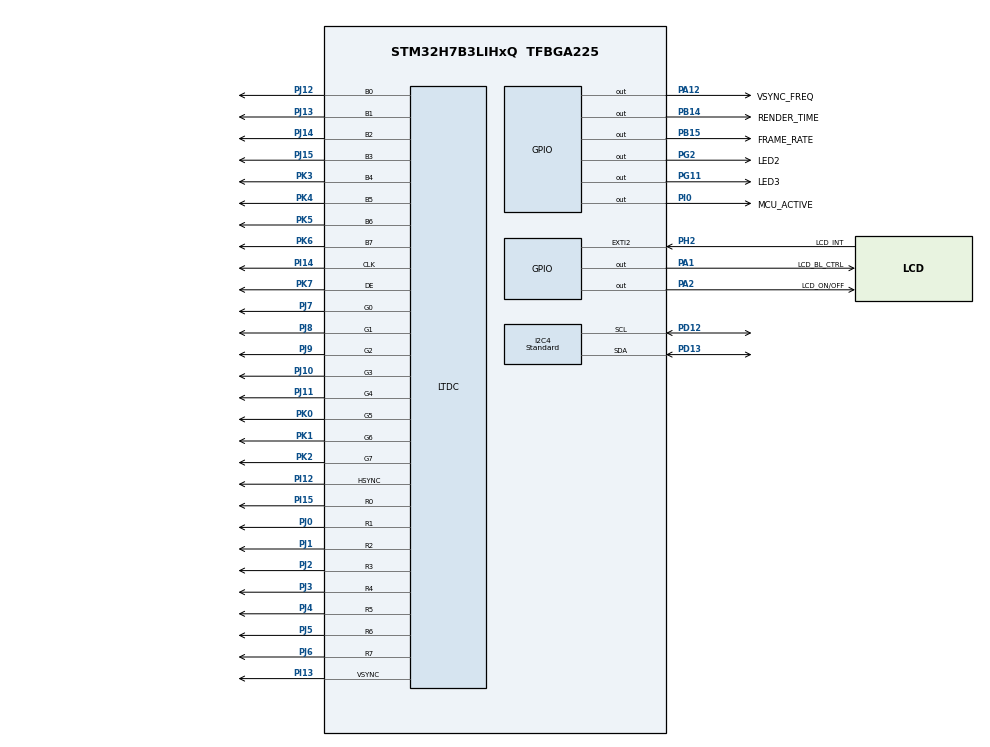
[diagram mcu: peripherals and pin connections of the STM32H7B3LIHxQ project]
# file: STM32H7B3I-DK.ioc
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CORTEX_M7.AccessPermission-Cortex_Memory_Protection_Unit_Region1_Settings=MPU_REGION_FULL_ACCESS
CORTEX_M7.AccessPermission-Cortex_Memory_Protection_Unit_Region2_Settings=MPU_REGION_FULL_ACCESS
CORTEX_M7.AccessPermission-Cortex_Memory_Protection_Unit_Region3_Settings=MPU_REGION_FULL_ACCESS
CORTEX_M7.BaseAddress-Cortex_Memory_Protection_Unit_Region0_Settings=0x90000000
CORTEX_M7.BaseAddress-Cortex_Memory_Protection_Unit_Region1_Settings=0x90000000
CORTEX_M7.BaseAddress-Cortex_Memory_Protection_Unit_Region2_Settings=0x24000000
CORTEX_M7.BaseAddress-Cortex_Memory_Protection_Unit_Region3_Settings=0x24000000
CORTEX_M7.CPU_DCache=Enabled
CORTEX_M7.CPU_ICache=Enabled
CORTEX_M7.DisableExec-Cortex_Memory_Protection_Unit_Region0_Settings=MPU_INSTRUCTION_ACCESS_DISABLE
CORTEX_M7.DisableExec-Cortex_Memory_Protection_Unit_Region1_Settings=MPU_INSTRUCTION_ACCESS_DISABLE
CORTEX_M7.DisableExec-Cortex_Memory_Protection_Unit_Region2_Settings=MPU_INSTRUCTION_ACCESS_DISABLE
CORTEX_M7.DisableExec-Cortex_Memory_Protection_Unit_Region3_Settings=MPU_INSTRUCTION_ACCESS_DISABLE
CORTEX_M7.Enable-Cortex_Memory_Protection_Unit_Region0_Settings=MPU_REGION_ENABLE
CORTEX_M7.Enable-Cortex_Memory_Protection_Unit_Region1_Settings=MPU_REGION_ENABLE
CORTEX_M7.Enable-Cortex_Memory_Protection_Unit_Region2_Settings=MPU_REGION_ENABLE
CORTEX_M7.Enable-Cortex_Memory_Protection_Unit_Region3_Settings=MPU_REGION_ENABLE
CORTEX_M7.IsBufferable-Cortex_Memory_Protection_Unit_Region3_Settings=MPU_ACCESS_BUFFERABLE
CORTEX_M7.IsCacheable-Cortex_Memory_Protection_Unit_Region1_Settings=MPU_ACCESS_CACHEABLE
CORTEX_M7.IsCacheable-Cortex_Memory_Protection_Unit_Region2_Settings=MPU_ACCESS_CACHEABLE
CORTEX_M7.IsCacheable-Cortex_Memory_Protection_Unit_Region3_Settings=MPU_ACCESS_CACHEABLE
CORTEX_M7.MPU_Control=MPU_PRIVILEGED_DEFAULT
CORTEX_M7.Size-Cortex_Memory_Protection_Unit_Region0_Settings=MPU_REGION_SIZE_256MB
CORTEX_M7.Size-Cortex_Memory_Protection_Unit_Region1_Settings=MPU_REGION_SIZE_64MB
CORTEX_M7.Size-Cortex_Memory_Protection_Unit_Region2_Settings=MPU_REGION_SIZE_1MB
CORTEX_M7.Size-Cortex_Memory_Protection_Unit_Region3_Settings=MPU_REGION_SIZE_256KB
DMA2D.ColorMode=DMA2D_OUTPUT_RGB565
FREERTOS.Tasks01=GUI_Task,24,4096,TouchGFX_Task,As weak,NULL,Dynamic,NULL,NULL
FREERTOS.configTOTAL_HEAP_SIZE=32768
I2C4.Analog_Filter=I2C_ANALOGFILTER_DISABLE
I2C4.I2C_Fall_Time=0
I2C4.I2C_Rise_Time=0
I2C4.I2C_Speed_Mode=I2C_Standard
I2C4.Speed=100
I2C4.Timing=0x30808BD0
LTDC.ActiveH=272
LTDC.ActiveW=480
LTDC.Alpha_L0=255
LTDC.BlendingFactor1_L0=LTDC_BLENDING_FACTOR1_CA
LTDC.BlendingFactor2_L0=LTDC_BLENDING_FACTOR2_CA
LTDC.Blue_L0=255
LTDC.HBP=2
LTDC.HFP=32
LTDC.HSync=41
LTDC.ImageHeight_L0=272
LTDC.ImageWidth_L0=480
LTDC.Layers=0
LTDC.PixelFormat_L0=LTDC_PIXEL_FORMAT_RGB888
LTDC.VSync=10
LTDC.WindowX1_L0=480
LTDC.WindowY1_L0=272
Mcu.Family=STM32H7
Mcu.Name=STM32H7B3LIHxQ
Mcu.Package=TFBGA225
NVIC.DMA2D_IRQn=true\:5\:0\:true\:false\:true\:true\:true\:true
NVIC.EXTI2_IRQn=true\:5\:0\:false\:false\:true\:true\:true\:true
NVIC.LTDC_IRQn=true\:5\:0\:false\:false\:true\:true\:true\:true
NVIC.OCTOSPI1_IRQn=true\:5\:0\:false\:false\:true\:true\:true\:true
NVIC.PriorityGroup=NVIC_PRIORITYGROUP_4
NVIC.TIM6_DAC_IRQn=true\:0\:0\:false\:false\:true\:false\:false\:true
NVIC.TimeBase=TIM6_DAC_IRQn
NVIC.TimeBaseIP=TIM6
OCTOSPI1.ChipSelectBoundary=0
OCTOSPI1.ChipSelectHighTime=2
OCTOSPI1.ClockPrescaler=3
OCTOSPI1.DeviceSize=26
OCTOSPI1.Refresh=0
PA1.GPIO_Label=LCD_BL_CTRL
PA1.GPIO_ModeDefaultOutputPP=GPIO_MODE_OUTPUT_PP
PA1.GPIO_PuPd=GPIO_NOPULL
PA1.GPIO_Speed=GPIO_SPEED_FREQ_LOW
PA1.PinState=GPIO_PIN_RESET
PA1.Signal=GPIO_Output
PA12.GPIO_Label=VSYNC_FREQ
PA12.Signal=GPIO_Output
PA2.GPIO_Label=LCD_ON/OFF
PA2.GPIO_ModeDefaultOutputPP=GPIO_MODE_OUTPUT_PP
PA2.GPIO_PuPd=GPIO_PULLUP
PA2.GPIO_Speed=GPIO_SPEED_FREQ_LOW
PA2.PinState=GPIO_PIN_RESET
PA2.Signal=GPIO_Output
PB14.GPIO_Label=RENDER_TIME
PB14.Signal=GPIO_Output
PB15.GPIO_Label=FRAME_RATE
PB15.Signal=GPIO_Output
PD12.GPIO_Speed=GPIO_SPEED_FREQ_HIGH
PD12.Mode=I2C
PD12.Signal=I2C4_SCL
PD13.GPIO_Speed=GPIO_SPEED_FREQ_HIGH
PD13.Mode=I2C
PD13.Signal=I2C4_SDA
PG11.GPIO_Label=LED3
PG11.Signal=GPIO_Output
PG2.GPIO_Label=LED2
PG2.Signal=GPIO_Output
PH0-OSC_IN.Mode=HSE-External-Oscillator
PH0-OSC_IN.Signal=RCC_OSC_IN
PH1-OSC_OUT.Mode=HSE-External-Oscillator
PH1-OSC_OUT.Signal=RCC_OSC_OUT
PH2.GPIO_Label=LCD_INT
PH2.GPIO_PuPd=GPIO_PULLUP
PH2.Signal=GPXTI2
PI0.GPIO_Label=MCU_ACTIVE
PI0.Signal=GPIO_Output
PI12.Mode=RGB888
PI12.Signal=LTDC_HSYNC
PI13.Mode=RGB888
PI13.Signal=LTDC_VSYNC
PI14.Mode=RGB888
PI14.Signal=LTDC_CLK
PI15.Mode=RGB888
PI15.Signal=LTDC_R0
PJ0.Mode=RGB888
PJ0.Signal=LTDC_R1
PJ1.Mode=RGB888
PJ1.Signal=LTDC_R2
PJ10.Mode=RGB888
PJ10.Signal=LTDC_G3
PJ11.Mode=RGB888
PJ11.Signal=LTDC_G4
PJ12.Mode=RGB888
PJ12.Signal=LTDC_B0
PJ13.Mode=RGB888
PJ13.Signal=LTDC_B1
PJ14.Mode=RGB888
PJ14.Signal=LTDC_B2
PJ15.Mode=RGB888
PJ15.Signal=LTDC_B3
PJ2.Mode=RGB888
PJ2.Signal=LTDC_R3
PJ3.Mode=RGB888
PJ3.Signal=LTDC_R4
PJ4.Mode=RGB888
PJ4.Signal=LTDC_R5
PJ5.Mode=RGB888
PJ5.Signal=LTDC_R6
PJ6.Mode=RGB888
PJ6.Signal=LTDC_R7
PJ7.Mode=RGB888
PJ7.Signal=LTDC_G0
PJ8.Mode=RGB888
PJ8.Signal=LTDC_G1
PJ9.Mode=RGB888
PJ9.Signal=LTDC_G2
PK0.Mode=RGB888
PK0.Signal=LTDC_G5
PK1.Mode=RGB888
PK1.Signal=LTDC_G6
PK2.Mode=RGB888
PK2.Signal=LTDC_G7
PK3.Mode=RGB888
PK3.Signal=LTDC_B4
PK4.Mode=RGB888
PK4.Signal=LTDC_B5
PK5.Mode=RGB888
PK5.Signal=LTDC_B6
PK6.Mode=RGB888
PK6.Signal=LTDC_B7
PK7.GPIO_PuPd=GPIO_NOPULL
PK7.Mode=RGB888
PK7.Signal=LTDC_DE
ProjectManager.HeapSize=0x1000
ProjectManager.StackSize=0x1000
ProjectManager.TargetToolchain=STM32CubeIDE
RCC.ADCFreq_Value=133000000
RCC.APB1Freq_Value=140000000
RCC.APB2Freq_Value=140000000
RCC.APB3Freq_Value=140000000
RCC.APB4Freq_Value=140000000
RCC.CKPERSourceSelection=RCC_CLKPSOURCE_HSE
RCC.CortexFreq_Value=280000000
RCC.DIVM1=12
RCC.DIVM2=24
RCC.DIVM3=24
RCC.DIVN1=280
RCC.DIVN2=266
RCC.DIVN3=201
RCC.DIVR3=21
RCC.HCLKFreq_Value=140000000
RCC.HPRE=RCC_HCLK_DIV2
RCC.HSIDiv=RCC_PLLSAIDIVR_2
RCC.PLL2FRACN=0
RCC.PLL3FRACN=5462
RCC.PLLFRACN=0
RCC.PLLSourceVirtual=RCC_PLLSOURCE_HSE
RCC.PWR_Regulator_Voltage_Scale=PWR_REGULATOR_VOLTAGE_SCALE0
RCC.QSPICLockSelection=RCC_OSPICLKSOURCE_PLL2
RCC.SYSCLKFreq_VALUE=280000000
RCC.SYSCLKSource=RCC_SYSCLKSOURCE_PLLCLK
RCC.SupplySource=PWR_DIRECT_SMPS_SUPPLY
RCC.USBFreq_Value=280000000
STMicroelectronics.X-CUBE-TOUCHGFX.4.15.0.ApplicationCcGraphicsJjApplication=TouchGFXOoGenerator
STMicroelectronics.X-CUBE-TOUCHGFX.4.15.0.tgfx_address1=0x24040000
STMicroelectronics.X-CUBE-TOUCHGFX.4.15.0.tgfx_address2=0x2409FA00
STMicroelectronics.X-CUBE-TOUCHGFX.4.15.0.tgfx_buffering_strategy=Double
STMicroelectronics.X-CUBE-TOUCHGFX.4.15.0.tgfx_display_interface=disp_ltdc
STMicroelectronics.X-CUBE-TOUCHGFX.4.15.0.tgfx_hardware_accelerator=dma_2d
STMicroelectronics.X-CUBE-TOUCHGFX.4.15.0.tgfx_location=Allocate
STMicroelectronics.X-CUBE-TOUCHGFX.4.15.0.tgfx_pixel_format=RGB888\:24
STMicroelectronics.X-CUBE-TOUCHGFX.4.15.0.tgfx_vsync=vsync_ltdc
VP_CRC_VS_CRC.Mode=CRC_Activate
VP_DMA2D_VS_DMA2D.Mode=DMA2D_Activate
VP_FREERTOS_VS_CMSIS_V2.Mode=CMSIS_V2
VP_OCTOSPI1_VS_octo.Mode=octo_mode
VP_STMicroelectronics.X-CUBE-TOUCHGFX_VS_GraphicsJjApplication_4.15.0.Mode=GraphicsJjApplication
VP_SYS_VS_tim6.Mode=TIM6
board=custom

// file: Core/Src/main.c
/* USER CODE BEGIN Header */
/**
  ******************************************************************************
  * @file           : main.c
  * @brief          : Main program body
  ******************************************************************************
  * @attention
  *
  * <h2><center>&copy; Copyright (c) 2019 STMicroelectronics.
  * All rights reserved.</center></h2>
  *
  * This software component is licensed by ST under Ultimate Liberty license
  * SLA0044, the "License"; You may not use this file except in compliance with
  * the License. You may obtain a copy of the License at:
  *                             www.st.com/SLA0044
  *
  ******************************************************************************
  */
/* USER CODE END Header */
#include "main.h"
#include "cmsis_os.h"
#include "app_touchgfx.h"

/* USER CODE BEGIN Includes */
#include "stm32h7b3i_discovery_ospi.h"
/* USER CODE END Includes */

CRC_HandleTypeDef hcrc;

DMA2D_HandleTypeDef hdma2d;

I2C_HandleTypeDef hi2c4;

LTDC_HandleTypeDef hltdc;

OSPI_HandleTypeDef hospi1;

/* Definitions for GUI_Task */
osThreadId_t GUI_TaskHandle;
const osThreadAttr_t GUI_Task_attributes = {
  .name = "GUI_Task",
  .priority = (osPriority_t) osPriorityNormal,
  .stack_size = 4096 * 4
};

void SystemClock_Config(void);
static void MPU_Config(void);
static void MX_CRC_Init(void);
static void MX_GPIO_Init(void);
static void MX_DMA2D_Init(void);
static void MX_LTDC_Init(void);
static void MX_I2C4_Init(void);
static void MX_OCTOSPI1_Init(void);
void TouchGFX_Task(void *argument);

int main(void)
{

  /* MPU Configuration--------------------------------------------------------*/
  MPU_Config();

  /* Enable I-Cache---------------------------------------------------------*/
  SCB_EnableICache();

  /* Enable D-Cache---------------------------------------------------------*/
  SCB_EnableDCache();

  /* MCU Configuration--------------------------------------------------------*/

  /* Reset of all peripherals, Initializes the Flash interface and the Systick. */
  HAL_Init();

  /* Configure the system clock */
  SystemClock_Config();

  /* Initialize all configured peripherals */
  MX_CRC_Init();
  MX_GPIO_Init();
  MX_DMA2D_Init();
  MX_LTDC_Init();
  MX_I2C4_Init();
  MX_OCTOSPI1_Init();
  MX_TouchGFX_Init();

  /* Init scheduler */
  osKernelInitialize();

  /* Create the thread(s) */
  /* creation of GUI_Task */
  GUI_TaskHandle = osThreadNew(TouchGFX_Task, NULL, &GUI_Task_attributes);

  /* Start scheduler */
  osKernelStart();

  /* We should never get here as control is now taken by the scheduler */
  /* Infinite loop */
  while (1)
  {

  }
}

void SystemClock_Config(void)
{
  RCC_OscInitTypeDef RCC_OscInitStruct = {0};
  RCC_ClkInitTypeDef RCC_ClkInitStruct = {0};
  RCC_PeriphCLKInitTypeDef PeriphClkInitStruct = {0};

  /** Supply configuration update enable
  */
  HAL_PWREx_ConfigSupply(PWR_DIRECT_SMPS_SUPPLY);
  /** Configure the main internal regulator output voltage
  */
  __HAL_PWR_VOLTAGESCALING_CONFIG(PWR_REGULATOR_VOLTAGE_SCALE0);

  while(!__HAL_PWR_GET_FLAG(PWR_FLAG_VOSRDY)) {}
  /** Macro to configure the PLL clock source
  */
  __HAL_RCC_PLL_PLLSOURCE_CONFIG(RCC_PLLSOURCE_HSE);
  /** Initializes the RCC Oscillators according to the specified parameters
  * in the RCC_OscInitTypeDef structure.
  */
  RCC_OscInitStruct.OscillatorType = RCC_OSCILLATORTYPE_HSE;
  RCC_OscInitStruct.HSEState = RCC_HSE_ON;
  RCC_OscInitStruct.PLL.PLLState = RCC_PLL_ON;
  RCC_OscInitStruct.PLL.PLLSource = RCC_PLLSOURCE_HSE;
  RCC_OscInitStruct.PLL.PLLM = 12;
  RCC_OscInitStruct.PLL.PLLN = 280;
  RCC_OscInitStruct.PLL.PLLP = 2;
  RCC_OscInitStruct.PLL.PLLQ = 2;
  RCC_OscInitStruct.PLL.PLLR = 2;
  RCC_OscInitStruct.PLL.PLLRGE = RCC_PLL1VCIRANGE_1;
  RCC_OscInitStruct.PLL.PLLVCOSEL = RCC_PLL1VCOWIDE;
  RCC_OscInitStruct.PLL.PLLFRACN = 0;
  if (HAL_RCC_OscConfig(&RCC_OscInitStruct) != HAL_OK)
  {
    Error_Handler();
  }
  /** Initializes the CPU, AHB and APB buses clocks
  */
  RCC_ClkInitStruct.ClockType = RCC_CLOCKTYPE_HCLK|RCC_CLOCKTYPE_SYSCLK
                              |RCC_CLOCKTYPE_PCLK1|RCC_CLOCKTYPE_PCLK2
                              |RCC_CLOCKTYPE_D3PCLK1|RCC_CLOCKTYPE_D1PCLK1;
  RCC_ClkInitStruct.SYSCLKSource = RCC_SYSCLKSOURCE_PLLCLK;
  RCC_ClkInitStruct.SYSCLKDivider = RCC_SYSCLK_DIV1;
  RCC_ClkInitStruct.AHBCLKDivider = RCC_HCLK_DIV2;
  RCC_ClkInitStruct.APB3CLKDivider = RCC_APB3_DIV1;
  RCC_ClkInitStruct.APB1CLKDivider = RCC_APB1_DIV1;
  RCC_ClkInitStruct.APB2CLKDivider = RCC_APB2_DIV1;
  RCC_ClkInitStruct.APB4CLKDivider = RCC_APB4_DIV1;

  if (HAL_RCC_ClockConfig(&RCC_ClkInitStruct, FLASH_LATENCY_3) != HAL_OK)
  {
    Error_Handler();
  }
  PeriphClkInitStruct.PeriphClockSelection = RCC_PERIPHCLK_LTDC|RCC_PERIPHCLK_I2C4
                              |RCC_PERIPHCLK_OSPI;
  PeriphClkInitStruct.PLL2.PLL2M = 24;
  PeriphClkInitStruct.PLL2.PLL2N = 266;
  PeriphClkInitStruct.PLL2.PLL2P = 2;
  PeriphClkInitStruct.PLL2.PLL2Q = 2;
  PeriphClkInitStruct.PLL2.PLL2R = 2;
  PeriphClkInitStruct.PLL2.PLL2RGE = RCC_PLL2VCIRANGE_0;
  PeriphClkInitStruct.PLL2.PLL2VCOSEL = RCC_PLL2VCOMEDIUM;
  PeriphClkInitStruct.PLL2.PLL2FRACN = 0;
  PeriphClkInitStruct.PLL3.PLL3M = 24;
  PeriphClkInitStruct.PLL3.PLL3N = 201;
  PeriphClkInitStruct.PLL3.PLL3P = 2;
  PeriphClkInitStruct.PLL3.PLL3Q = 2;
  PeriphClkInitStruct.PLL3.PLL3R = 21;
  PeriphClkInitStruct.PLL3.PLL3RGE = RCC_PLL3VCIRANGE_0;
  PeriphClkInitStruct.PLL3.PLL3VCOSEL = RCC_PLL3VCOMEDIUM;
  PeriphClkInitStruct.PLL3.PLL3FRACN = 5462;
  PeriphClkInitStruct.OspiClockSelection = RCC_OSPICLKSOURCE_PLL2;
  PeriphClkInitStruct.I2c4ClockSelection = RCC_I2C4CLKSOURCE_D3PCLK1;
  if (HAL_RCCEx_PeriphCLKConfig(&PeriphClkInitStruct) != HAL_OK)
  {
    Error_Handler();
  }
}

static void MX_CRC_Init(void)
{

  hcrc.Instance = CRC;
  hcrc.Init.DefaultPolynomialUse = DEFAULT_POLYNOMIAL_ENABLE;
  hcrc.Init.DefaultInitValueUse = DEFAULT_INIT_VALUE_ENABLE;
  hcrc.Init.InputDataInversionMode = CRC_INPUTDATA_INVERSION_NONE;
  hcrc.Init.OutputDataInversionMode = CRC_OUTPUTDATA_INVERSION_DISABLE;
  hcrc.InputDataFormat = CRC_INPUTDATA_FORMAT_BYTES;
  if (HAL_CRC_Init(&hcrc) != HAL_OK)
  {
    Error_Handler();
  }

}

static void MX_DMA2D_Init(void)
{

  hdma2d.Instance = DMA2D;
  hdma2d.Init.Mode = DMA2D_M2M;
  hdma2d.Init.ColorMode = DMA2D_OUTPUT_RGB565;
  hdma2d.Init.OutputOffset = 0;
  hdma2d.Init.BytesSwap = DMA2D_BYTES_REGULAR;
  hdma2d.Init.LineOffsetMode = DMA2D_LOM_PIXELS;
  hdma2d.LayerCfg[1].InputOffset = 0;
  hdma2d.LayerCfg[1].InputColorMode = DMA2D_INPUT_RGB565;
  hdma2d.LayerCfg[1].AlphaMode = DMA2D_NO_MODIF_ALPHA;
  hdma2d.LayerCfg[1].InputAlpha = 0;
  hdma2d.LayerCfg[1].AlphaInverted = DMA2D_REGULAR_ALPHA;
  hdma2d.LayerCfg[1].RedBlueSwap = DMA2D_RB_REGULAR;
  hdma2d.LayerCfg[1].ChromaSubSampling = DMA2D_NO_CSS;
  if (HAL_DMA2D_Init(&hdma2d) != HAL_OK)
  {
    Error_Handler();
  }
  if (HAL_DMA2D_ConfigLayer(&hdma2d, 1) != HAL_OK)
  {
    Error_Handler();
  }

}

static void MX_I2C4_Init(void)
{

  hi2c4.Instance = I2C4;
  hi2c4.Init.Timing = 0x30808BD0;
  hi2c4.Init.OwnAddress1 = 0;
  hi2c4.Init.AddressingMode = I2C_ADDRESSINGMODE_7BIT;
  hi2c4.Init.DualAddressMode = I2C_DUALADDRESS_DISABLE;
  hi2c4.Init.OwnAddress2 = 0;
  hi2c4.Init.OwnAddress2Masks = I2C_OA2_NOMASK;
  hi2c4.Init.GeneralCallMode = I2C_GENERALCALL_DISABLE;
  hi2c4.Init.NoStretchMode = I2C_NOSTRETCH_DISABLE;
  if (HAL_I2C_Init(&hi2c4) != HAL_OK)
  {
    Error_Handler();
  }
  /** Configure Analogue filter
  */
  if (HAL_I2CEx_ConfigAnalogFilter(&hi2c4, I2C_ANALOGFILTER_DISABLE) != HAL_OK)
  {
    Error_Handler();
  }
  /** Configure Digital filter
  */
  if (HAL_I2CEx_ConfigDigitalFilter(&hi2c4, 0) != HAL_OK)
  {
    Error_Handler();
  }

}

static void MX_LTDC_Init(void)
{

  LTDC_LayerCfgTypeDef pLayerCfg = {0};
  LTDC_LayerCfgTypeDef pLayerCfg1 = {0};

  hltdc.Instance = LTDC;
  hltdc.Init.HSPolarity = LTDC_HSPOLARITY_AL;
  hltdc.Init.VSPolarity = LTDC_VSPOLARITY_AL;
  hltdc.Init.DEPolarity = LTDC_DEPOLARITY_AL;
  hltdc.Init.PCPolarity = LTDC_PCPOLARITY_IPC;
  hltdc.Init.HorizontalSync = 40;
  hltdc.Init.VerticalSync = 9;
  hltdc.Init.AccumulatedHBP = 42;
  hltdc.Init.AccumulatedVBP = 11;
  hltdc.Init.AccumulatedActiveW = 522;
  hltdc.Init.AccumulatedActiveH = 283;
  hltdc.Init.TotalWidth = 554;
  hltdc.Init.TotalHeigh = 285;
  hltdc.Init.Backcolor.Blue = 0;
  hltdc.Init.Backcolor.Green = 0;
  hltdc.Init.Backcolor.Red = 0;
  if (HAL_LTDC_Init(&hltdc) != HAL_OK)
  {
    Error_Handler();
  }
  pLayerCfg.WindowX0 = 0;
  pLayerCfg.WindowX1 = 480;
  pLayerCfg.WindowY0 = 0;
  pLayerCfg.WindowY1 = 272;
  pLayerCfg.PixelFormat = LTDC_PIXEL_FORMAT_RGB888;
  pLayerCfg.Alpha = 255;
  pLayerCfg.Alpha0 = 0;
  pLayerCfg.BlendingFactor1 = LTDC_BLENDING_FACTOR1_CA;
  pLayerCfg.BlendingFactor2 = LTDC_BLENDING_FACTOR2_CA;
  pLayerCfg.FBStartAdress = 0;
  pLayerCfg.ImageWidth = 480;
  pLayerCfg.ImageHeight = 272;
  pLayerCfg.Backcolor.Blue = 255;
  pLayerCfg.Backcolor.Green = 0;
  pLayerCfg.Backcolor.Red = 0;
  if (HAL_LTDC_ConfigLayer(&hltdc, &pLayerCfg, 0) != HAL_OK)
  {
    Error_Handler();
  }
  pLayerCfg1.WindowX0 = 0;
  pLayerCfg1.WindowX1 = 0;
  pLayerCfg1.WindowY0 = 0;
  pLayerCfg1.WindowY1 = 0;
  pLayerCfg1.Alpha = 0;
  pLayerCfg1.Alpha0 = 0;
  pLayerCfg1.BlendingFactor1 = LTDC_BLENDING_FACTOR1_CA;
  pLayerCfg1.BlendingFactor2 = LTDC_BLENDING_FACTOR2_CA;
  pLayerCfg1.FBStartAdress = GFXMMU_VIRTUAL_BUFFER0_BASE;
  pLayerCfg1.ImageWidth = 0;
  pLayerCfg1.ImageHeight = 0;
  pLayerCfg1.Backcolor.Blue = 0;
  pLayerCfg1.Backcolor.Green = 0;
  pLayerCfg1.Backcolor.Red = 0;
  if (HAL_LTDC_ConfigLayer(&hltdc, &pLayerCfg1, 1) != HAL_OK)
  {
    Error_Handler();
  }

}

static void MX_OCTOSPI1_Init(void)
{

  /* OCTOSPI1 parameter configuration*/
  hospi1.Instance = OCTOSPI1;
  hospi1.Init.FifoThreshold = 1;
  hospi1.Init.DualQuad = HAL_OSPI_DUALQUAD_DISABLE;
  hospi1.Init.MemoryType = HAL_OSPI_MEMTYPE_MICRON;
  hospi1.Init.DeviceSize = 26;
  hospi1.Init.ChipSelectHighTime = 2;
  hospi1.Init.FreeRunningClock = HAL_OSPI_FREERUNCLK_DISABLE;
  hospi1.Init.ClockMode = HAL_OSPI_CLOCK_MODE_0;
  hospi1.Init.WrapSize = HAL_OSPI_WRAP_NOT_SUPPORTED;
  hospi1.Init.ClockPrescaler = 3;
  hospi1.Init.SampleShifting = HAL_OSPI_SAMPLE_SHIFTING_NONE;
  hospi1.Init.DelayHoldQuarterCycle = HAL_OSPI_DHQC_DISABLE;
  hospi1.Init.ChipSelectBoundary = 0;
  hospi1.Init.ClkChipSelectHighTime = 0;
  hospi1.Init.DelayBlockBypass = HAL_OSPI_DELAY_BLOCK_BYPASSED;
  hospi1.Init.MaxTran = 0;
  hospi1.Init.Refresh = 0;
  if (HAL_OSPI_Init(&hospi1) != HAL_OK)
  {
    Error_Handler();
  }
  /* USER CODE BEGIN OCTOSPI1_Init 2 */
  BSP_OSPI_NOR_Init_t Flash;
  Flash.InterfaceMode = BSP_OSPI_NOR_OPI_MODE;
  Flash.TransferRate  = BSP_OSPI_NOR_DTR_TRANSFER;
  BSP_OSPI_NOR_DeInit(0);
  int32_t RetVal = BSP_OSPI_NOR_Init(0, &Flash);
  if(RetVal != BSP_ERROR_NONE)
  {
    Error_Handler();
  }
  RetVal = BSP_OSPI_NOR_EnableMemoryMappedMode(0);
  if(RetVal != BSP_ERROR_NONE)
  {
    Error_Handler();
  }
  /* USER CODE END OCTOSPI1_Init 2 */

}

static void MX_GPIO_Init(void)
{
  GPIO_InitTypeDef GPIO_InitStruct = {0};

  /* GPIO Ports Clock Enable */
  __HAL_RCC_GPIOK_CLK_ENABLE();
  __HAL_RCC_GPIOG_CLK_ENABLE();
  __HAL_RCC_GPIOJ_CLK_ENABLE();
  __HAL_RCC_GPIOI_CLK_ENABLE();
  __HAL_RCC_GPIOA_CLK_ENABLE();
  __HAL_RCC_GPIOD_CLK_ENABLE();
  __HAL_RCC_GPIOH_CLK_ENABLE();
  __HAL_RCC_GPIOB_CLK_ENABLE();

  /*Configure GPIO pin Output Level */
  HAL_GPIO_WritePin(GPIOG, LED3_Pin|LED2_Pin, GPIO_PIN_RESET);

  /*Configure GPIO pin Output Level */
  HAL_GPIO_WritePin(MCU_ACTIVE_GPIO_Port, MCU_ACTIVE_Pin, GPIO_PIN_RESET);

  /*Configure GPIO pin Output Level */
  HAL_GPIO_WritePin(GPIOA, VSYNC_FREQ_Pin|LCD_BL_CTRL_Pin|LCD_ON_OFF_Pin, GPIO_PIN_RESET);

  /*Configure GPIO pin Output Level */
  HAL_GPIO_WritePin(GPIOB, RENDER_TIME_Pin|FRAME_RATE_Pin, GPIO_PIN_RESET);

  /*Configure GPIO pins : LED3_Pin LED2_Pin */
  GPIO_InitStruct.Pin = LED3_Pin|LED2_Pin;
  GPIO_InitStruct.Mode = GPIO_MODE_OUTPUT_PP;
  GPIO_InitStruct.Pull = GPIO_NOPULL;
  GPIO_InitStruct.Speed = GPIO_SPEED_FREQ_LOW;
  HAL_GPIO_Init(GPIOG, &GPIO_InitStruct);

  /*Configure GPIO pin : MCU_ACTIVE_Pin */
  GPIO_InitStruct.Pin = MCU_ACTIVE_Pin;
  GPIO_InitStruct.Mode = GPIO_MODE_OUTPUT_PP;
  GPIO_InitStruct.Pull = GPIO_NOPULL;
  GPIO_InitStruct.Speed = GPIO_SPEED_FREQ_LOW;
  HAL_GPIO_Init(MCU_ACTIVE_GPIO_Port, &GPIO_InitStruct);

  /*Configure GPIO pins : VSYNC_FREQ_Pin LCD_BL_CTRL_Pin */
  GPIO_InitStruct.Pin = VSYNC_FREQ_Pin|LCD_BL_CTRL_Pin;
  GPIO_InitStruct.Mode = GPIO_MODE_OUTPUT_PP;
  GPIO_InitStruct.Pull = GPIO_NOPULL;
  GPIO_InitStruct.Speed = GPIO_SPEED_FREQ_LOW;
  HAL_GPIO_Init(GPIOA, &GPIO_InitStruct);

  /*Configure GPIO pin : LCD_INT_Pin */
  GPIO_InitStruct.Pin = LCD_INT_Pin;
  GPIO_InitStruct.Mode = GPIO_MODE_IT_RISING;
  GPIO_InitStruct.Pull = GPIO_PULLUP;
  HAL_GPIO_Init(LCD_INT_GPIO_Port, &GPIO_InitStruct);

  /*Configure GPIO pins : RENDER_TIME_Pin FRAME_RATE_Pin */
  GPIO_InitStruct.Pin = RENDER_TIME_Pin|FRAME_RATE_Pin;
  GPIO_InitStruct.Mode = GPIO_MODE_OUTPUT_PP;
  GPIO_InitStruct.Pull = GPIO_NOPULL;
  GPIO_InitStruct.Speed = GPIO_SPEED_FREQ_LOW;
  HAL_GPIO_Init(GPIOB, &GPIO_InitStruct);

  /*Configure GPIO pin : LCD_ON_OFF_Pin */
  GPIO_InitStruct.Pin = LCD_ON_OFF_Pin;
  GPIO_InitStruct.Mode = GPIO_MODE_OUTPUT_PP;
  GPIO_InitStruct.Pull = GPIO_PULLUP;
  GPIO_InitStruct.Speed = GPIO_SPEED_FREQ_LOW;
  HAL_GPIO_Init(LCD_ON_OFF_GPIO_Port, &GPIO_InitStruct);

  /* EXTI interrupt init*/
  HAL_NVIC_SetPriority(EXTI2_IRQn, 5, 0);
  HAL_NVIC_EnableIRQ(EXTI2_IRQn);

}

/* USER CODE BEGIN Header_TouchGFX_Task */
/**
  * @brief  Function implementing the GUI_Task thread.
  *
  *         Marked as __weak in order to overwrite this function by
  *         TouchGFX_Task(void *argument) provided by TouchGFX Generator
  *         in TouchGFX/App/app_touchgfx.c
  *
  * @param  argument: Not used
  * @retval None
  */
/* USER CODE END Header_TouchGFX_Task */
__weak void TouchGFX_Task(void *argument)
{
  for(;;)
  {
    osDelay(1);
  }
}

/* MPU Configuration */

void MPU_Config(void)
{
  MPU_Region_InitTypeDef MPU_InitStruct = {0};

  /* Disables the MPU */
  HAL_MPU_Disable();
  /** Initializes and configures the Region and the memory to be protected
  */
  MPU_InitStruct.Enable = MPU_REGION_ENABLE;
  MPU_InitStruct.Number = MPU_REGION_NUMBER0;
  MPU_InitStruct.BaseAddress = 0x90000000;
  MPU_InitStruct.Size = MPU_REGION_SIZE_256MB;
  MPU_InitStruct.SubRegionDisable = 0x0;
  MPU_InitStruct.TypeExtField = MPU_TEX_LEVEL0;
  MPU_InitStruct.AccessPermission = MPU_REGION_NO_ACCESS;
  MPU_InitStruct.DisableExec = MPU_INSTRUCTION_ACCESS_DISABLE;
  MPU_InitStruct.IsShareable = MPU_ACCESS_NOT_SHAREABLE;
  MPU_InitStruct.IsCacheable = MPU_ACCESS_NOT_CACHEABLE;
  MPU_InitStruct.IsBufferable = MPU_ACCESS_NOT_BUFFERABLE;

  HAL_MPU_ConfigRegion(&MPU_InitStruct);
  /** Initializes and configures the Region and the memory to be protected
  */
  MPU_InitStruct.Enable = MPU_REGION_ENABLE;
  MPU_InitStruct.Number = MPU_REGION_NUMBER1;
  MPU_InitStruct.BaseAddress = 0x90000000;
  MPU_InitStruct.Size = MPU_REGION_SIZE_64MB;
  MPU_InitStruct.SubRegionDisable = 0x0;
  MPU_InitStruct.TypeExtField = MPU_TEX_LEVEL0;
  MPU_InitStruct.AccessPermission = MPU_REGION_FULL_ACCESS;
  MPU_InitStruct.DisableExec = MPU_INSTRUCTION_ACCESS_DISABLE;
  MPU_InitStruct.IsShareable = MPU_ACCESS_NOT_SHAREABLE;
  MPU_InitStruct.IsCacheable = MPU_ACCESS_CACHEABLE;
  MPU_InitStruct.IsBufferable = MPU_ACCESS_NOT_BUFFERABLE;

  HAL_MPU_ConfigRegion(&MPU_InitStruct);
  /** Initializes and configures the Region and the memory to be protected
  */
  MPU_InitStruct.Enable = MPU_REGION_ENABLE;
  MPU_InitStruct.Number = MPU_REGION_NUMBER2;
  MPU_InitStruct.BaseAddress = 0x24000000;
  MPU_InitStruct.Size = MPU_REGION_SIZE_1MB;
  MPU_InitStruct.SubRegionDisable = 0x0;
  MPU_InitStruct.TypeExtField = MPU_TEX_LEVEL0;
  MPU_InitStruct.AccessPermission = MPU_REGION_FULL_ACCESS;
  MPU_InitStruct.DisableExec = MPU_INSTRUCTION_ACCESS_DISABLE;
  MPU_InitStruct.IsShareable = MPU_ACCESS_NOT_SHAREABLE;
  MPU_InitStruct.IsCacheable = MPU_ACCESS_CACHEABLE;
  MPU_InitStruct.IsBufferable = MPU_ACCESS_NOT_BUFFERABLE;

  HAL_MPU_ConfigRegion(&MPU_InitStruct);
  /** Initializes and configures the Region and the memory to be protected
  */
  MPU_InitStruct.Enable = MPU_REGION_ENABLE;
  MPU_InitStruct.Number = MPU_REGION_NUMBER3;
  MPU_InitStruct.BaseAddress = 0x24000000;
  MPU_InitStruct.Size = MPU_REGION_SIZE_256KB;
  MPU_InitStruct.SubRegionDisable = 0x0;
  MPU_InitStruct.TypeExtField = MPU_TEX_LEVEL0;
  MPU_InitStruct.AccessPermission = MPU_REGION_FULL_ACCESS;
  MPU_InitStruct.DisableExec = MPU_INSTRUCTION_ACCESS_DISABLE;
  MPU_InitStruct.IsShareable = MPU_ACCESS_NOT_SHAREABLE;
  MPU_InitStruct.IsCacheable = MPU_ACCESS_CACHEABLE;
  MPU_InitStruct.IsBufferable = MPU_ACCESS_BUFFERABLE;

  HAL_MPU_ConfigRegion(&MPU_InitStruct);
  /* Enables the MPU */
  HAL_MPU_Enable(MPU_PRIVILEGED_DEFAULT);

}
void HAL_TIM_PeriodElapsedCallback(TIM_HandleTypeDef *htim)
{
  if (htim->Instance == TIM6) {
    HAL_IncTick();
  }
}

void Error_Handler(void)
{
}

/************************ (C) COPYRIGHT STMicroelectronics *****END OF FILE****/
